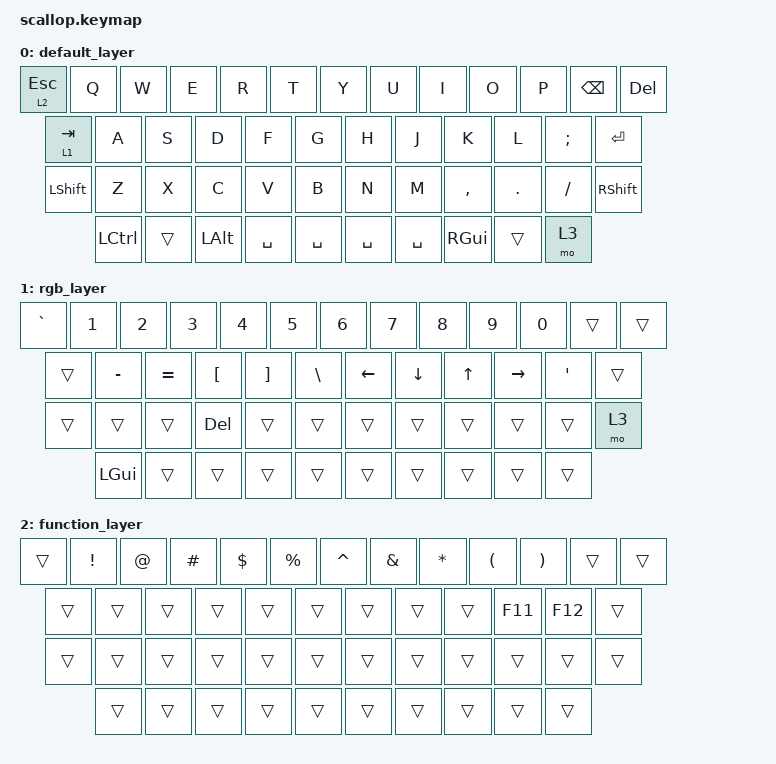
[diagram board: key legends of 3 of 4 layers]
/*
 * Copyright (c) 2021 Nick Winans
 *
 * SPDX-License-Identifier: MIT
 */

/*
 * This is the default keymap. You probably shouldn't bother editing it. Changes won't be picked up from here.
 * It exists to give you something to copy back into the config folder if your own keymap is too far gone to salvage.
 */

#include <behaviors.dtsi>
#include <dt-bindings/zmk/keys.h>
#include <dt-bindings/zmk/rgb.h>
#include <dt-bindings/zmk/bt.h>

/ {
    keymap {
        compatible = "zmk,keymap";

        default_layer {
// ------------------------------------------------------------------------------------------
// | ESC |  1  |  2  |  3  |  4  |  5  |  6  |  7  |  8  |  9  |  0  |  -  |  =  |   BKSP   |
// | TAB  |  Q  |  W  |  E  |  R  |  T  |  Y  |  U  |  I  |  O  |  P  |  [  |  ]  |   "|"   |
// | CAPS  |  A  |  S  |  D  |  F  |  G  |  H  |  J  |  K  |  L  |  ;  |  '  |     ENTER    |
// |  SHIFT  |  Z  |  X  |  C  |  V  |  B  |  N  |  M  |  ,  |  .  |  /  |      SHIFT       |
// |  CTL  |  WIN  |  ALT  |            SPACE              |  ALT  |  WIN  |  MO(1) |  CTL  |
// ------------------------------------------------------------------------------------------
            bindings = <
    &lt 2 ESC  &kp Q  &kp W  &kp E  &kp R  &kp T  &kp Y  &kp U  &kp I  &kp O  &kp P  &kp BSPC  &kp DEL
    &lt 1 TAB  &kp A  &kp S  &kp D  &kp F  &kp G  &kp H  &kp J  &kp K  &kp L  &kp SEMI &kp RET
    &kp LSHFT   &kp Z  &kp X  &kp C  &kp V  &kp B  &kp N  &kp M  &kp COMMA &kp DOT &kp FSLH  &kp RSHFT
    &kp LCTRL &trans &kp LALT        &kp SPACE &kp SPACE &kp SPACE  &kp SPACE       &kp RGUI  &trans  &mo 3
            >;
        };

        rgb_layer {
// ------------------------------------------------------------------------------------------------
// | BT CLR | F1  | F2  | F3  | F4  | F5  | F6  | F7  | F8  | F9  | F10  | F11 | F12 | EFFECT REV |
// |  BT 1   |   |  UP |   | HUEUP | SATUP | BRIUP | SPDUP |   |     |    |     |     |           |
// |   BT 2   | LT |  DN  | RT | HUEDN | SATDN | BRIDN | SPDDN |   |     |   |     |  EFFECT FORW |
// |    BT 3     |     |      |      |     |     |     |     |     |     |     |                  |
// |   BT 4  |      |      |             TOG RGB                | PRT SCR |       |       |  DEL  |
// ------------------------------------------------------------------------------------------------
            bindings = <
    &kp GRAVE  &kp N1  &kp N2  &kp N3  &kp N4  &kp N5  &kp N6  &kp N7  &kp N8  &kp N9  &kp N0  &trans &trans
    &trans  &kp MINUS  &kp EQUAL  &kp LBKT  &kp RBKT  &kp BSLH  &kp LEFT  &kp DOWN  &kp UP  &kp RIGHT  &kp APOS &trans
    &trans   &trans &trans  &kp DEL  &trans  &trans  &trans &trans  &trans &trans &trans   &mo 3
    &kp LGUI &trans &trans             &trans  &trans  &trans  &trans        &trans  &trans  &trans
            >;
        };

        function_layer {
// ------------------------------------------------------------------------------------------------
// | BT CLR | F1  | F2  | F3  | F4  | F5  | F6  | F7  | F8  | F9  | F10  | F11 | F12 | EFFECT REV |
// |  BT 1   |   |  UP |   | HUEUP | SATUP | BRIUP | SPDUP |   |     |    |     |     |           |
// |   BT 2   | LT |  DN  | RT | HUEDN | SATDN | BRIDN | SPDDN |   |     |   |     |  EFFECT FORW |
// |    BT 3     |     |      |      |     |     |     |     |     |     |     |                  |
// |   BT 4  |      |      |             TOG RGB                | PRT SCR |       |       |  DEL  |
// ------------------------------------------------------------------------------------------------
            bindings = <
    &trans  &kp EXCL  &kp AT  &kp HASH  &kp DLLR  &kp PRCNT  &kp CARET  &kp AMPS  &kp STAR  &kp LPAR  &kp RPAR  &trans &trans
    &trans  &trans  &trans  &trans  &trans  &trans  &trans  &trans  &trans  &kp F11  &kp F12 &trans
    &trans   &trans &trans  &trans  &trans  &trans  &trans &trans  &trans &trans &trans          &trans
    &trans &trans &trans             &trans  &trans  &trans  &trans         &trans  &trans  &trans
            >;
        };

        bluetooth_layer {
// ------------------------------------------------------------------------------------------------
// | BT CLR | F1  | F2  | F3  | F4  | F5  | F6  | F7  | F8  | F9  | F10  | F11 | F12 | EFFECT REV |
// |  BT 1   |   |  UP |   | HUEUP | SATUP | BRIUP | SPDUP |   |     |    |     |     |           |
// |   BT 2   | LT |  DN  | RT | HUEDN | SATDN | BRIDN | SPDDN |   |     |   |     |  EFFECT FORW |
// |    BT 3     |     |      |      |     |     |     |     |     |     |     |                  |
// |   BT 4  |      |      |             TOG RGB                | PRT SCR |       |       |  DEL  |
// ------------------------------------------------------------------------------------------------
            bindings = <
    &trans &trans  &trans  &trans  &trans &trans &trans  &trans &trans  &trans  &trans  &trans
    &trans  &trans  &trans  &trans  &trans  &trans  &trans  &trans  &trans  &trans  &trans &trans
    &bt BT_CLR   &bt BT_SEL 0 &bt BT_SEL 1  &trans  &trans  &trans  &trans &trans  &trans &trans &trans          &trans
    &bootloader &sys_reset &trans             &trans  &trans  &trans  &trans                     &trans  &trans  &trans
            >;
        };
    };
};
